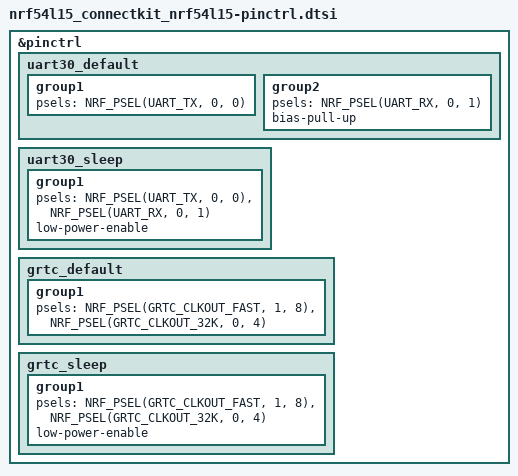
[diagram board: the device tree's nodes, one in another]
/*
 * Copyright (c) 2016-2025 Makerdiary <https://makerdiary.com>
 * SPDX-License-Identifier: Apache-2.0
 */

&pinctrl {
	/omit-if-no-ref/ uart30_default: uart30_default {
		group1 {
			psels = <NRF_PSEL(UART_TX, 0, 0)>;
		};
		group2 {
			psels = <NRF_PSEL(UART_RX, 0, 1)>;
			bias-pull-up;
		};
	};

	/omit-if-no-ref/ uart30_sleep: uart30_sleep {
		group1 {
			psels = <NRF_PSEL(UART_TX, 0, 0)>,
				<NRF_PSEL(UART_RX, 0, 1)>;
			low-power-enable;
		};
	};

	/omit-if-no-ref/ grtc_default: grtc_default {
		group1 {
			psels = <NRF_PSEL(GRTC_CLKOUT_FAST, 1, 8)>,
				<NRF_PSEL(GRTC_CLKOUT_32K, 0, 4)>;
		};
	};

	/omit-if-no-ref/ grtc_sleep: grtc_sleep {
		group1 {
			psels = <NRF_PSEL(GRTC_CLKOUT_FAST, 1, 8)>,
				<NRF_PSEL(GRTC_CLKOUT_32K, 0, 4)>;
			low-power-enable;
		};
	};
};
